AUTOSAR XML (schema 4-0-3)
standard types defined: Boolean, UInt8
package /AUTOSAR_Platform/DataConstrs
  range DC_Boolean: raw 0..1
package /PATAC/MSM/ComponentTypes
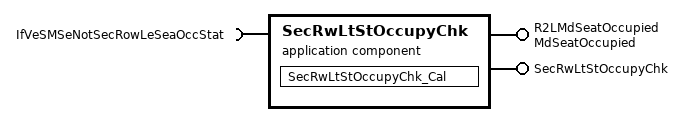
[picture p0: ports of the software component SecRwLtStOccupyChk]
  application sw component type SecRwLtStOccupyChk
    provide port R2LMdSeatOccupied: nonqueued-sender-com-spec{data-element=MdSeatOccupied/Val, init-value=0}, provided-interface=MdSeatOccupied
    provide port SecRwLtStOccupyChk: server-com-spec{operation=Cal, queue-length=1}, provided-interface=SecRwLtStOccupyChk
    require port IfVeSMSeNotSecRowLeSeaOccStat: nonqueued-receiver-com-spec{data-element=IfVeSMSeNotSecRowLeSeaOccStat/Val, filter=data-filter-type=ALWAYS, init-value=0}, required-interface=IfVeSMSeNotSecRowLeSeaOccStat
    behavior SecRwLtStOccupyChk_InternalBehavior
      operation invoked event OIT_SecRwLtStOccupyChk_Cal_SecRwLtStOccupyChk_Cal: start-on-event=SecRwLtStOccupyChk_Cal, operation=SecRwLtStOccupyChk.Cal
      runnable SecRwLtStOccupyChk_Cal
        data-receive-point-by-arguments:
          access REC_IfVeSMSeNotSecRowLeSeaOccStat_Val: accessed-variable=IfVeSMSeNotSecRowLeSeaOccStat.Val
        data-send-points:
          access SEND_R2LMdSeatOccupied_Val: accessed-variable=R2LMdSeatOccupied.Val
  swc implementation SecRwLtStOccupyChk_Implementation: behavior=SecRwLtStOccupyChk_InternalBehavior
    code-descriptors:
      code Default: artifact-descriptors=autosar-engineering-object={short-label=Default, category=SWSRC}
package /PATAC/MSM/ModeAdjust/DataType
  impl type SeatOccupiedSts1: category=VALUE, base-type=UInt8, sw-calibration-access=READ-ONLY, compu {0=SeatOccupiedSts_Unknown, 1=SeatOccupiedSts_Empty, 2=SeatOccupiedSts_Occupied, 3=SeatOccupiedSts_DataNotAvailable}, type-emitter=RTE
package /PATAC/MSM/ModeAdjust/Interfaces
  sender receiver interface IfVeSMSeNotSecRowLeSeaOccStat: invalidation-policy{data-element=IfVeSMSeNotSecRowLeSeaOccStat/Val, handle-invalid=DONT-INVALIDATE}
    data Val: type=SeatOccupiedSts1
package /PATAC/MSM/ModeAdjust/PortInterface
  client server interface SecRwLtStOccupyChk
    operation Cal
  sender receiver interface MdSeatOccupied: invalidation-policy{data-element=MdSeatOccupied/Val, handle-invalid=DONT-INVALIDATE}
    data Val: type=Boolean
